AUTOSAR XML (schema 4-2-2)
package /STELLANTIS/EPT/ASWCs
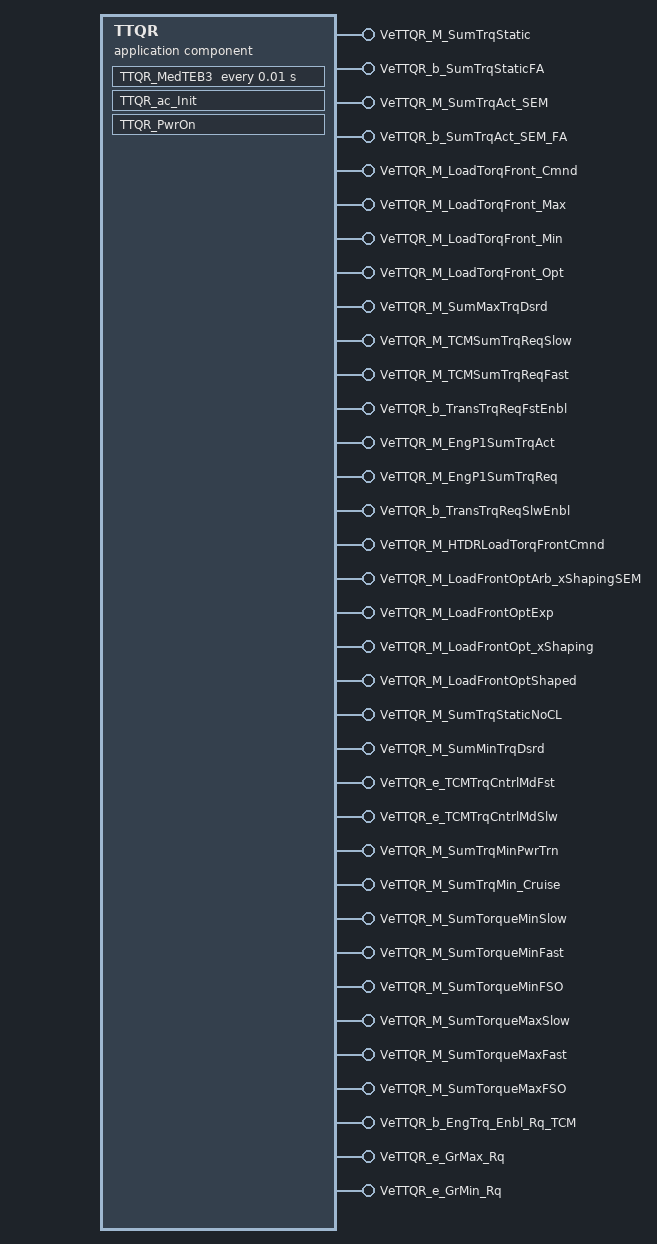
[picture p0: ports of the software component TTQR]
  application sw component type TTQR
    35 x provide port:
      VeTTQR_M_SumTrqStatic: nonqueued-sender-com-spec{data-element=Value, init-value=0}, provided-interface=VeTTQR_M_SumTrqStatic
      VeTTQR_b_SumTrqStaticFA: nonqueued-sender-com-spec{data-element=Value, init-value=0}, provided-interface=VeTTQR_b_SumTrqStaticFA
      VeTTQR_M_SumTrqAct_SEM: nonqueued-sender-com-spec{data-element=Value, init-value=0}, provided-interface=VeTTQR_M_SumTrqAct_SEM
      VeTTQR_b_SumTrqAct_SEM_FA: nonqueued-sender-com-spec{data-element=Value, init-value=0}, provided-interface=VeTTQR_b_SumTrqAct_SEM_FA
      VeTTQR_M_LoadTorqFront_Cmnd: nonqueued-sender-com-spec{data-element=Value, init-value=0}, provided-interface=VeTTQR_M_LoadTorqFront_Cmnd
      VeTTQR_M_LoadTorqFront_Max: nonqueued-sender-com-spec{data-element=Value, init-value=0}, provided-interface=VeTTQR_M_LoadTorqFront_Max
      VeTTQR_M_LoadTorqFront_Min: nonqueued-sender-com-spec{data-element=Value, init-value=0}, provided-interface=VeTTQR_M_LoadTorqFront_Min
      VeTTQR_M_LoadTorqFront_Opt: nonqueued-sender-com-spec{data-element=Value, init-value=0}, provided-interface=VeTTQR_M_LoadTorqFront_Opt
      VeTTQR_M_SumMaxTrqDsrd: nonqueued-sender-com-spec{data-element=Value, init-value=0}, provided-interface=VeTTQR_M_SumMaxTrqDsrd
      VeTTQR_M_TCMSumTrqReqSlow: nonqueued-sender-com-spec{data-element=Value, init-value=0}, provided-interface=VeTTQR_M_TCMSumTrqReqSlow
      VeTTQR_M_TCMSumTrqReqFast: nonqueued-sender-com-spec{data-element=Value, init-value=0}, provided-interface=VeTTQR_M_TCMSumTrqReqFast
      VeTTQR_b_TransTrqReqFstEnbl: nonqueued-sender-com-spec{data-element=Value, init-value=0}, provided-interface=VeTTQR_b_TransTrqReqFstEnbl
      VeTTQR_M_EngP1SumTrqAct: nonqueued-sender-com-spec{data-element=Value, init-value=0}, provided-interface=VeTTQR_M_EngP1SumTrqAct
      VeTTQR_M_EngP1SumTrqReq: nonqueued-sender-com-spec{data-element=Value, init-value=0}, provided-interface=VeTTQR_M_EngP1SumTrqReq
      VeTTQR_b_TransTrqReqSlwEnbl: nonqueued-sender-com-spec{data-element=Value, init-value=0}, provided-interface=VeTTQR_b_TransTrqReqSlwEnbl
      VeTTQR_M_HTDRLoadTorqFrontCmnd: nonqueued-sender-com-spec{data-element=Value, init-value=0}, provided-interface=VeTTQR_M_HTDRLoadTorqFrontCmnd
      VeTTQR_M_LoadFrontOptArb_xShapingSEM: nonqueued-sender-com-spec{data-element=Value, init-value=0}, provided-interface=VeTTQR_M_LoadFrontOptArb_xShapingSEM
      VeTTQR_M_LoadFrontOptExp: nonqueued-sender-com-spec{data-element=Value, init-value=0}, provided-interface=VeTTQR_M_LoadFrontOptExp
      VeTTQR_M_LoadFrontOpt_xShaping: nonqueued-sender-com-spec{data-element=Value, init-value=0}, provided-interface=VeTTQR_M_LoadFrontOpt_xShaping
      VeTTQR_M_LoadFrontOptShaped: nonqueued-sender-com-spec{data-element=Value, init-value=0}, provided-interface=VeTTQR_M_LoadFrontOptShaped
      VeTTQR_M_SumTrqStaticNoCL: nonqueued-sender-com-spec{data-element=Value, init-value=0}, provided-interface=VeTTQR_M_SumTrqStaticNoCL
      VeTTQR_M_SumMinTrqDsrd: nonqueued-sender-com-spec{data-element=Value, init-value=0}, provided-interface=VeTTQR_M_SumMinTrqDsrd
      VeTTQR_e_TCMTrqCntrlMdFst: nonqueued-sender-com-spec{data-element=Value, init-value=CeTINR_e_None}, provided-interface=VeTTQR_e_TCMTrqCntrlMdFst
      VeTTQR_e_TCMTrqCntrlMdSlw: nonqueued-sender-com-spec{data-element=Value, init-value=CeTINR_e_None}, provided-interface=VeTTQR_e_TCMTrqCntrlMdSlw
      VeTTQR_M_SumTrqMinPwrTrn: nonqueued-sender-com-spec{data-element=Value, init-value=0}, provided-interface=VeTTQR_M_SumTrqMinPwrTrn
      VeTTQR_M_SumTrqMin_Cruise: nonqueued-sender-com-spec{data-element=Value, init-value=0}, provided-interface=VeTTQR_M_SumTrqMin_Cruise
      VeTTQR_M_SumTorqueMinSlow: nonqueued-sender-com-spec{data-element=Value, init-value=0}, provided-interface=VeTTQR_M_SumTorqueMinSlow
      VeTTQR_M_SumTorqueMinFast: nonqueued-sender-com-spec{data-element=Value, init-value=0}, provided-interface=VeTTQR_M_SumTorqueMinFast
      VeTTQR_M_SumTorqueMinFSO: nonqueued-sender-com-spec{data-element=Value, init-value=0}, provided-interface=VeTTQR_M_SumTorqueMinFSO
      VeTTQR_M_SumTorqueMaxSlow: nonqueued-sender-com-spec{data-element=Value, init-value=0}, provided-interface=VeTTQR_M_SumTorqueMaxSlow
      VeTTQR_M_SumTorqueMaxFast: nonqueued-sender-com-spec{data-element=Value, init-value=0}, provided-interface=VeTTQR_M_SumTorqueMaxFast
      VeTTQR_M_SumTorqueMaxFSO: nonqueued-sender-com-spec{data-element=Value, init-value=0}, provided-interface=VeTTQR_M_SumTorqueMaxFSO
      VeTTQR_b_EngTrq_Enbl_Rq_TCM: nonqueued-sender-com-spec{data-element=Value, init-value=0}, provided-interface=VeTTQR_b_EngTrq_Enbl_Rq_TCM
      VeTTQR_e_GrMax_Rq: nonqueued-sender-com-spec{data-element=Value, init-value=CeTRNR_e_Neutral}, provided-interface=VeTTQR_e_GrMax_Rq
      VeTTQR_e_GrMin_Rq: nonqueued-sender-com-spec{data-element=Value, init-value=CeTRNR_e_Neutral}, provided-interface=VeTTQR_e_GrMin_Rq
    behavior IB_TTQR: data-type-mapping=msADTtoIDTMapping, handle-termination-and-restart=NO-SUPPORT
      timing event Event_MedTEB3: start-on-event=TTQR_MedTEB3, period=0.01
      init event Event_TTQR_ac_Init: start-on-event=TTQR_ac_Init
      init event Event_PwrOn: start-on-event=TTQR_PwrOn
      runnable TTQR_ac_Init
        data-send-points:
          4 x access:
            OUT_VeTTQR_e_TCMTrqCntrlMdFst_Value: accessed-variable=VeTTQR_e_TCMTrqCntrlMdFst.Value
            OUT_VeTTQR_e_TCMTrqCntrlMdSlw_Value: accessed-variable=VeTTQR_e_TCMTrqCntrlMdSlw.Value
            OUT_VeTTQR_e_GrMax_Rq_Value: accessed-variable=VeTTQR_e_GrMax_Rq.Value
            OUT_VeTTQR_e_GrMin_Rq_Value: accessed-variable=VeTTQR_e_GrMin_Rq.Value
      runnable TTQR_PwrOn
        data-send-points:
          35 x access:
            OUT_VeTTQR_b_EngTrq_Enbl_Rq_TCM_Value: accessed-variable=VeTTQR_b_EngTrq_Enbl_Rq_TCM.Value
            OUT_VeTTQR_M_EngP1SumTrqAct_Value: accessed-variable=VeTTQR_M_EngP1SumTrqAct.Value
            OUT_VeTTQR_M_EngP1SumTrqReq_Value: accessed-variable=VeTTQR_M_EngP1SumTrqReq.Value
            OUT_VeTTQR_M_LoadTorqFront_Cmnd_Value: accessed-variable=VeTTQR_M_LoadTorqFront_Cmnd.Value
            OUT_VeTTQR_M_HTDRLoadTorqFrontCmnd_Value: accessed-variable=VeTTQR_M_HTDRLoadTorqFrontCmnd.Value
            OUT_VeTTQR_M_LoadTorqFront_Max_Value: accessed-variable=VeTTQR_M_LoadTorqFront_Max.Value
            OUT_VeTTQR_M_LoadTorqFront_Opt_Value: accessed-variable=VeTTQR_M_LoadTorqFront_Opt.Value
            OUT_VeTTQR_M_LoadTorqFront_Min_Value: accessed-variable=VeTTQR_M_LoadTorqFront_Min.Value
            OUT_VeTTQR_M_SumTrqStaticNoCL_Value: accessed-variable=VeTTQR_M_SumTrqStaticNoCL.Value
            OUT_VeTTQR_M_SumTrqStatic_Value: accessed-variable=VeTTQR_M_SumTrqStatic.Value
            OUT_VeTTQR_M_SumMaxTrqDsrd_Value: accessed-variable=VeTTQR_M_SumMaxTrqDsrd.Value
            OUT_VeTTQR_M_TCMSumTrqReqFast_Value: accessed-variable=VeTTQR_M_TCMSumTrqReqFast.Value
            OUT_VeTTQR_M_TCMSumTrqReqSlow_Value: accessed-variable=VeTTQR_M_TCMSumTrqReqSlow.Value
            OUT_VeTTQR_b_TransTrqReqSlwEnbl_Value: accessed-variable=VeTTQR_b_TransTrqReqSlwEnbl.Value
            OUT_VeTTQR_b_TransTrqReqFstEnbl_Value: accessed-variable=VeTTQR_b_TransTrqReqFstEnbl.Value
            OUT_VeTTQR_M_LoadFrontOptArb_xShapingSEM_Value: accessed-variable=VeTTQR_M_LoadFrontOptArb_xShapingSEM.Value
            OUT_VeTTQR_M_LoadFrontOptExp_Value: accessed-variable=VeTTQR_M_LoadFrontOptExp.Value
            OUT_VeTTQR_M_LoadFrontOptShaped_Value: accessed-variable=VeTTQR_M_LoadFrontOptShaped.Value
            OUT_VeTTQR_M_LoadFrontOpt_xShaping_Value: accessed-variable=VeTTQR_M_LoadFrontOpt_xShaping.Value
            OUT_VeTTQR_M_SumMinTrqDsrd_Value: accessed-variable=VeTTQR_M_SumMinTrqDsrd.Value
            OUT_VeTTQR_b_SumTrqStaticFA_Value: accessed-variable=VeTTQR_b_SumTrqStaticFA.Value
            OUT_VeTTQR_e_TCMTrqCntrlMdSlw_Value: accessed-variable=VeTTQR_e_TCMTrqCntrlMdSlw.Value
            OUT_VeTTQR_e_TCMTrqCntrlMdFst_Value: accessed-variable=VeTTQR_e_TCMTrqCntrlMdFst.Value
            OUT_VeTTQR_M_SumTrqMinPwrTrn_Value: accessed-variable=VeTTQR_M_SumTrqMinPwrTrn.Value
            OUT_VeTTQR_M_SumTrqMin_Cruise_Value: accessed-variable=VeTTQR_M_SumTrqMin_Cruise.Value
            OUT_VeTTQR_M_SumTorqueMinFSO_Value: accessed-variable=VeTTQR_M_SumTorqueMinFSO.Value
            OUT_VeTTQR_M_SumTorqueMaxSlow_Value: accessed-variable=VeTTQR_M_SumTorqueMaxSlow.Value
            OUT_VeTTQR_M_SumTorqueMinFast_Value: accessed-variable=VeTTQR_M_SumTorqueMinFast.Value
            OUT_VeTTQR_M_SumTorqueMinSlow_Value: accessed-variable=VeTTQR_M_SumTorqueMinSlow.Value
            OUT_VeTTQR_M_SumTorqueMaxFast_Value: accessed-variable=VeTTQR_M_SumTorqueMaxFast.Value
            OUT_VeTTQR_M_SumTorqueMaxFSO_Value: accessed-variable=VeTTQR_M_SumTorqueMaxFSO.Value
            OUT_VeTTQR_e_GrMax_Rq_Value: accessed-variable=VeTTQR_e_GrMax_Rq.Value
            OUT_VeTTQR_e_GrMin_Rq_Value: accessed-variable=VeTTQR_e_GrMin_Rq.Value
            OUT_VeTTQR_M_SumTrqAct_SEM_Value: accessed-variable=VeTTQR_M_SumTrqAct_SEM.Value
            OUT_VeTTQR_b_SumTrqAct_SEM_FA_Value: accessed-variable=VeTTQR_b_SumTrqAct_SEM_FA.Value
      runnable TTQR_MedTEB3
        data-send-points:
          18 x access:
            OUT_VeTTQR_M_EngP1SumTrqAct_Value: accessed-variable=VeTTQR_M_EngP1SumTrqAct.Value
            OUT_VeTTQR_M_EngP1SumTrqReq_Value: accessed-variable=VeTTQR_M_EngP1SumTrqReq.Value
            OUT_VeTTQR_M_LoadTorqFront_Cmnd_Value: accessed-variable=VeTTQR_M_LoadTorqFront_Cmnd.Value
            OUT_VeTTQR_M_HTDRLoadTorqFrontCmnd_Value: accessed-variable=VeTTQR_M_HTDRLoadTorqFrontCmnd.Value
            OUT_VeTTQR_M_SumTrqStaticNoCL_Value: accessed-variable=VeTTQR_M_SumTrqStaticNoCL.Value
            OUT_VeTTQR_M_SumTrqStatic_Value: accessed-variable=VeTTQR_M_SumTrqStatic.Value
            OUT_VeTTQR_b_SumTrqStaticFA_Value: accessed-variable=VeTTQR_b_SumTrqStaticFA.Value
            OUT_VeTTQR_M_SumTrqAct_SEM_Value: accessed-variable=VeTTQR_M_SumTrqAct_SEM.Value
            OUT_VeTTQR_b_SumTrqAct_SEM_FA_Value: accessed-variable=VeTTQR_b_SumTrqAct_SEM_FA.Value
            OUT_VeTTQR_b_EngTrq_Enbl_Rq_TCM_Value: accessed-variable=VeTTQR_b_EngTrq_Enbl_Rq_TCM.Value
            OUT_VeTTQR_M_SumTorqueMinFSO_Value: accessed-variable=VeTTQR_M_SumTorqueMinFSO.Value
            OUT_VeTTQR_M_SumTorqueMaxSlow_Value: accessed-variable=VeTTQR_M_SumTorqueMaxSlow.Value
            OUT_VeTTQR_M_SumTorqueMinFast_Value: accessed-variable=VeTTQR_M_SumTorqueMinFast.Value
            OUT_VeTTQR_M_SumTorqueMinSlow_Value: accessed-variable=VeTTQR_M_SumTorqueMinSlow.Value
            OUT_VeTTQR_M_SumTorqueMaxFast_Value: accessed-variable=VeTTQR_M_SumTorqueMaxFast.Value
            OUT_VeTTQR_M_SumTorqueMaxFSO_Value: accessed-variable=VeTTQR_M_SumTorqueMaxFSO.Value
            OUT_VeTTQR_e_GrMax_Rq_Value: accessed-variable=VeTTQR_e_GrMax_Rq.Value
            OUT_VeTTQR_e_GrMin_Rq_Value: accessed-variable=VeTTQR_e_GrMin_Rq.Value
      4 x variation point proxy, all with category=CONDITION, condition-access=0:
        Variant_TTQR_DrvAllwdSumMaxTrqClip
        Variant_TTQR_FUNC
        Variant_TTQR_SingleMtrSumTrqLim
        Variant_TTQR_SumTrqCalc_TiPDCL
